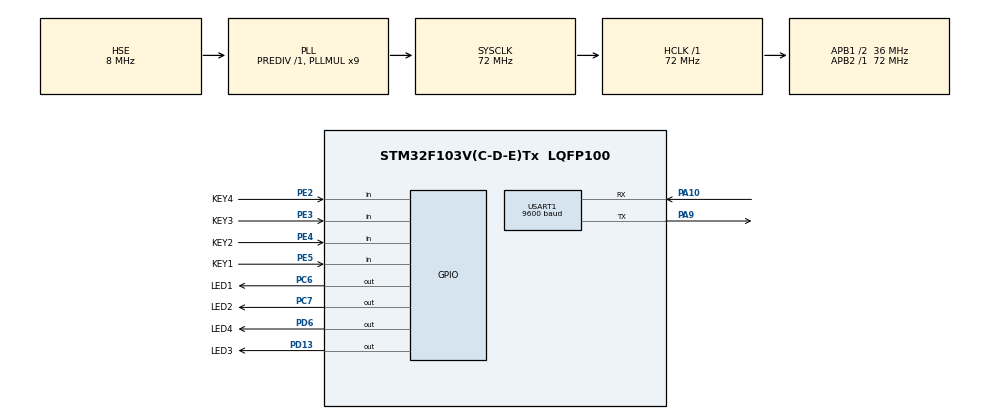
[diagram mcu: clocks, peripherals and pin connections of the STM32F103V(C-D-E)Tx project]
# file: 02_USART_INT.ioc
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Mcu.Family=STM32F1
Mcu.Name=STM32F103V(C-D-E)Tx
Mcu.Package=LQFP100
NVIC.PriorityGroup=NVIC_PRIORITYGROUP_4
NVIC.USART1_IRQn=true\:1\:0\:true\:false\:true\:true
OSC_IN.Mode=HSE-External-Oscillator
OSC_IN.Signal=RCC_OSC_IN
OSC_OUT.Mode=HSE-External-Oscillator
OSC_OUT.Signal=RCC_OSC_OUT
PA10.Mode=Asynchronous
PA10.Signal=USART1_RX
PA9.Mode=Asynchronous
PA9.Signal=USART1_TX
PC6.GPIO_Label=LED1
PC6.GPIO_Speed=GPIO_SPEED_FREQ_LOW
PC6.Signal=GPIO_Output
PC7.GPIO_Label=LED2
PC7.GPIO_ModeDefaultOutputPP=GPIO_MODE_OUTPUT_PP
PC7.GPIO_Speed=GPIO_SPEED_FREQ_LOW
PC7.Signal=GPIO_Output
PD13.GPIO_Label=LED3
PD13.Signal=GPIO_Output
PD6.GPIO_Label=LED4
PD6.Signal=GPIO_Output
PE2.GPIO_Label=KEY4
PE2.Signal=GPIO_Input
PE3.GPIO_Label=KEY3
PE3.Signal=GPIO_Input
PE4.GPIO_Label=KEY2
PE4.Signal=GPIO_Input
PE5.GPIO_Label=KEY1
PE5.Signal=GPIO_Input
ProjectManager.HeapSize=0x200
ProjectManager.StackSize=0x400
ProjectManager.TargetToolchain=SW4STM32
RCC.AHBFreq_Value=72000000
RCC.APB1CLKDivider=RCC_HCLK_DIV2
RCC.APB1Freq_Value=36000000
RCC.APB1TimFreq_Value=72000000
RCC.APB2Freq_Value=72000000
RCC.APB2TimFreq_Value=72000000
RCC.HCLKFreq_Value=72000000
RCC.PLLMUL=RCC_PLL_MUL9
RCC.PLLSourceVirtual=RCC_PLLSOURCE_HSE
RCC.SYSCLKFreq_VALUE=72000000
RCC.SYSCLKSource=RCC_SYSCLKSOURCE_PLLCLK
RCC.USBFreq_Value=72000000
USART1.BaudRate=9600
USART1.VirtualMode=VM_ASYNC
VP_SYS_VS_ND.Mode=No_Debug
board=custom

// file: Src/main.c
/* USER CODE BEGIN Header */
/**
  ******************************************************************************
  * @file           : main.c
  * @brief          : Main program body
  ******************************************************************************
  ** This notice applies to any and all portions of this file
  * that are not between comment pairs USER CODE BEGIN and
  * USER CODE END. Other portions of this file, whether
  * inserted by the user or by software development tools
  * are owned by their respective copyright owners.
  *
  * COPYRIGHT(c) 2019 STMicroelectronics
  *
  * Redistribution and use in source and binary forms, with or without modification,
  * are permitted provided that the following conditions are met:
  *   1. Redistributions of source code must retain the above copyright notice,
  *      this list of conditions and the following disclaimer.
  *   2. Redistributions in binary form must reproduce the above copyright notice,
  *      this list of conditions and the following disclaimer in the documentation
  *      and/or other materials provided with the distribution.
  *   3. Neither the name of STMicroelectronics nor the names of its contributors
  *      may be used to endorse or promote products derived from this software
  *      without specific prior written permission.
  *
  * THIS SOFTWARE IS PROVIDED BY THE COPYRIGHT HOLDERS AND CONTRIBUTORS "AS IS"
  * AND ANY EXPRESS OR IMPLIED WARRANTIES, INCLUDING, BUT NOT LIMITED TO, THE
  * IMPLIED WARRANTIES OF MERCHANTABILITY AND FITNESS FOR A PARTICULAR PURPOSE ARE
  * DISCLAIMED. IN NO EVENT SHALL THE COPYRIGHT HOLDER OR CONTRIBUTORS BE LIABLE
  * FOR ANY DIRECT, INDIRECT, INCIDENTAL, SPECIAL, EXEMPLARY, OR CONSEQUENTIAL
  * DAMAGES (INCLUDING, BUT NOT LIMITED TO, PROCUREMENT OF SUBSTITUTE GOODS OR
  * SERVICES; LOSS OF USE, DATA, OR PROFITS; OR BUSINESS INTERRUPTION) HOWEVER
  * CAUSED AND ON ANY THEORY OF LIABILITY, WHETHER IN CONTRACT, STRICT LIABILITY,
  * OR TORT (INCLUDING NEGLIGENCE OR OTHERWISE) ARISING IN ANY WAY OUT OF THE USE
  * OF THIS SOFTWARE, EVEN IF ADVISED OF THE POSSIBILITY OF SUCH DAMAGE.
  *
  ******************************************************************************
  */
/* USER CODE END Header */

#include "main.h"
#include "usart.h"
#include "gpio.h"

/* USER CODE BEGIN PV */
unsigned char tx_buff[] = {'0','1','2','3','4','5','6','7','8','9'};  // my code
unsigned char rx_buff[10];  // my code
/* USER CODE END PV */

void SystemClock_Config(void);

int main(void)
{

  /* MCU Configuration--------------------------------------------------------*/

  /* Reset of all peripherals, Initializes the Flash interface and the Systick. */
  HAL_Init();

  /* Configure the system clock */
  SystemClock_Config();

  /* Initialize all configured peripherals */
  MX_GPIO_Init();
  MX_USART1_UART_Init();
  /* USER CODE BEGIN 2 */

  /* Prepare to receive data and store data to rx_buff */
  /* When 10 bytes are received Rx Interrupt will be triggered */

  /* **In function UART_Receive_IT() RXNEIE in USART_CR1 is DISABLED.** */
  /* **In function HAL_UART_RxCpltCallback() RXNEIE in USART_CR1 need to be ENABLED.** */
  HAL_UART_Receive_IT(&huart1, rx_buff, 10);  // my code

  /* USER CODE END 2 */

  /* Infinite loop */
  while (1)
  {

    /* USER CODE BEGIN 3 */
    /* Send 10 bytes from tx_buff if KEY1 is pressed */
    if(!HAL_GPIO_ReadPin(KEY1_GPIO_Port, KEY1_Pin))
    {
      HAL_Delay(20);  // Key debounce
      if(HAL_GPIO_ReadPin(KEY1_GPIO_Port, KEY1_Pin))
      {
        HAL_UART_Transmit_IT(&huart1, tx_buff, 10);  // my code
      }
    }
  }
  /* USER CODE END 3 */
}

void SystemClock_Config(void)
{
  RCC_OscInitTypeDef RCC_OscInitStruct = {0};
  RCC_ClkInitTypeDef RCC_ClkInitStruct = {0};

  /**Initializes the CPU, AHB and APB busses clocks
  */
  RCC_OscInitStruct.OscillatorType = RCC_OSCILLATORTYPE_HSE;
  RCC_OscInitStruct.HSEState = RCC_HSE_ON;
  RCC_OscInitStruct.HSEPredivValue = RCC_HSE_PREDIV_DIV1;
  RCC_OscInitStruct.HSIState = RCC_HSI_ON;
  RCC_OscInitStruct.PLL.PLLState = RCC_PLL_ON;
  RCC_OscInitStruct.PLL.PLLSource = RCC_PLLSOURCE_HSE;
  RCC_OscInitStruct.PLL.PLLMUL = RCC_PLL_MUL9;
  if (HAL_RCC_OscConfig(&RCC_OscInitStruct) != HAL_OK)
  {
    Error_Handler();
  }
  /**Initializes the CPU, AHB and APB busses clocks
  */
  RCC_ClkInitStruct.ClockType = RCC_CLOCKTYPE_HCLK|RCC_CLOCKTYPE_SYSCLK
                              |RCC_CLOCKTYPE_PCLK1|RCC_CLOCKTYPE_PCLK2;
  RCC_ClkInitStruct.SYSCLKSource = RCC_SYSCLKSOURCE_PLLCLK;
  RCC_ClkInitStruct.AHBCLKDivider = RCC_SYSCLK_DIV1;
  RCC_ClkInitStruct.APB1CLKDivider = RCC_HCLK_DIV2;
  RCC_ClkInitStruct.APB2CLKDivider = RCC_HCLK_DIV1;

  if (HAL_RCC_ClockConfig(&RCC_ClkInitStruct, FLASH_LATENCY_2) != HAL_OK)
  {
    Error_Handler();
  }
}

/* USER CODE BEGIN 4 */
void HAL_UART_TxCpltCallback(UART_HandleTypeDef *huart)  // my code
{
//  __NOP();  // like "pass" in python
  HAL_GPIO_TogglePin(LED1_GPIO_Port, LED1_Pin);
}

void HAL_UART_RxCpltCallback(UART_HandleTypeDef *huart)  // my code
{
//  __NOP();  // like "pass" in python
  /* *RXNEIE in USART_CR1 is ENABLED again.* */
  HAL_UART_Receive_IT(&huart1, rx_buff, 10);  // my code
  HAL_GPIO_TogglePin(LED2_GPIO_Port, LED2_Pin);
}
/* USER CODE END 4 */

void Error_Handler(void)
{
}

/************************ (C) COPYRIGHT STMicroelectronics *****END OF FILE****/
